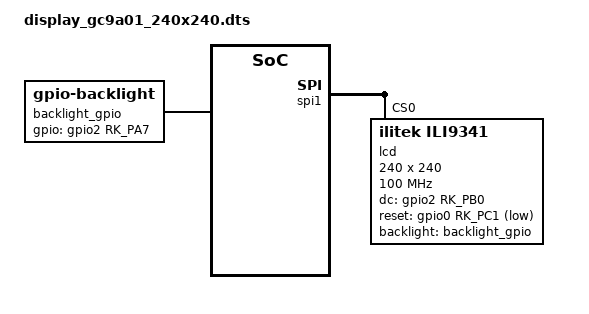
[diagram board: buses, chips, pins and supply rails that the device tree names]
/dts-v1/;
/plugin/;

#include <dt-bindings/gpio/gpio.h>
#include <dt-bindings/pinctrl/rockchip.h>

/ {
	fragment@0 {
		target = <&spi1>;

		__overlay__ {
			status = "okay";

			#address-cells = <1>;
			#size-cells = <0>;

			lcd@0 {
				status = "okay";
				compatible = "ilitek,ili9341";
				reg = <0>;
				spi-max-frequency = <100000000>;

				backlight = <&backlight_gpio>;
				dc-gpios = <&gpio2 RK_PB0 GPIO_ACTIVE_HIGH>;
				reset-gpios = <&gpio0 RK_PC1 GPIO_ACTIVE_LOW>;

				buswidth = <8>;
				width = <240>;
				height = <240>;
				bgr = <0>;
				rotate = <0>;
				init = <0x1000011		// Sleep mode off
					0x1000078		// Delay 120ms
					0x10000ef		// Inter Register Enable 2
					0x10000eb 0x14
					0x10000fe		// Inter Register Enable 1
					0x10000ef		// Inter Register Enable 2
					0x1000028		// DISPLAY OFF
					0x10000eb 0x14
					0x1000084 0x40
					0x1000085 0xff
					0x1000086 0xff
					0x1000087 0xff
					0x1000088 0x0a
					0x1000089 0x21
					0x100008a 0x00
					0x100008b 0x80
					0x100008c 0x01
					0x100008d 0x01
					0x100008e 0xff
					0x100008f 0xff
					0x10000b6 0x00 0x20
					0x100003a 0x05		// PIXEL FORMAT SET
					0x1000090 0x08 0x08 0x08 0x08
					0x10000bd 0x06
					0x10000bc 0x00
					0x10000ff 0x60 0x01 0x04
					0x10000c3 0x13		// Power Control 2
					0x10000c4 0x13		// Power Control 3
					0x10000c9 0x22		// Power Control 4
					0x10000be 0x11
					0x10000e1 0x10 0x0e
					0x10000df 0x21 0x0c 0x02
					0x10000f0 0x45 0x09 0x08 0x08 0x26 0x2a	// GAMMA 1
					0x10000f1 0x43 0x70 0x72 0x36 0x37 0x6f	// GAMMA 2
					0x10000f2 0x45 0x09 0x08 0x08 0x26 0x2a	// GAMMA 3
					0x10000f3 0x43 0x70 0x72 0x36 0x37 0x6f // GAMMA 4
					0x10000ed 0x1b 0x0b
					0x10000ae 0x77
					0x10000cd 0x63
					0x1000070 0x07 0x07 0x04 0x0e 0x0f 0x09 0x07 0x08 0x03
					0x10000e8 0x34			// Frame Rate
					0x1000062 0x18 0x0d 0x71 0xed 0x70 0x70 0x18 0x0f 0x71 0xef 0x70 0x70
					0x1000063 0x18 0x11 0x71 0xf1 0x70 0x70 0x18 0x13 0x71 0xf3 0x70 0x70
					0x1000064 0x28 0x29 0xf1 0x01 0xf1 0x00 0x07
					0x1000066 0x3c 0x00 0xcd 0x67 0x45 0x45 0x10 0x00 0x00 0x00
					0x1000067 0x00 0x3c 0x00 0x00 0x00 0x01 0x54 0x10 0x32 0x98
					0x1000074 0x10 0x85 0x80 0x00 0x00 0x4e 0x00
					0x1000098 0x3e 0x07
					0x1000021		// DISPLAY INVERSION
					0x1000035		// TEARING EFFECT LINE ON
					0x1000011		// SLEEP OUT MODE
					0x2000078		// DELAY : 120ms
					0x1000029		// DISPLAY ON
					0x2000014		// DELAY : 20ms
				>;

				pinctrl-names = "default";
				pinctrl-0 = <&display_pins>;

				display_pins: display-pins {
					rockchip,pins = <2 RK_PB0 0 &pcfg_pull_none>,
						<0 RK_PC1 0 &pcfg_pull_none>;
				};
			};
		};
	};

	fragment@1 {
		target-path = "/";

		__overlay__ {
			backlight_gpio: backlight-gpio {
				status = "okay";
				compatible = "gpio-backlight";

				gpios = <&gpio2 RK_PA7 GPIO_ACTIVE_HIGH>;
			};
		};
	};
};
